# M36B register map
File version: 0.1
TOSHIBA Cortex-M3 MCU
Registers are 32-bit, read-write, reset 0x0 unless marked. A register's access mark holds for its fields unless they carry their own. Offsets are from the block's base; lines under a group give offsets from that group; [hi:lo] are bit positions; {n}, {i} and the like mark numbered series; 'fields as' and 'values as' point back to an identical list; <NAME> marks a mode.

## Memory map
0x40040000 SSP0 size 0x28 — Synchronous Serial Port
0x40041000 SSP1 size 0x28
0x40042000 SSP2 size 0x28
0x40048000 UART0 blocks up to offset 0x4C — ARM Prime Cell PL011
0x40049000 UART1 blocks up to offset 0x4C
0x4004C000 DMAA blocks up to offset 0x50 — DMA Controller
0x4004D000 DMAB blocks up to offset 0x50
0x40050000 AD blocks up to offset 0x78 — Analog-to-Digital Converter (AD)
0x4005C000 EXB blocks up to offset 0x50 — External Bus Interface(EXB)
0x40066000 ADILV blocks up to offset 0x14 — ADC
0x400C0000 PA blocks up to offset 0x3C — General Purpose Input_Output Port (PA)
0x400C0100 PB blocks up to offset 0x3C — General Purpose Input_Output Port (PB)
0x400C0200 PC blocks up to offset 0x3C — General Purpose Input_Output Port (PC)
0x400C0400 PE blocks up to offset 0x3C — General Purpose Input_Output Port (PE)
0x400C0500 PF blocks up to offset 0x3C — General Purpose Input_Output Port (PF)
0x400C0600 PG blocks up to offset 0x3C — General Purpose Input_Output Port (PG)
0x400C0700 PH blocks up to offset 0x3C — General Purpose Input_Output Port (PH)
0x400C0800 PI blocks up to offset 0x3C — General Purpose Input_Output Port (PI)
0x400C0900 PJ blocks up to offset 0x3C — General Purpose Input_Output Port (PJ)
0x400C0A00 PK blocks up to offset 0x3C — General Purpose Input_Output Port (PK)
0x400C0B00 PL blocks up to offset 0x3C — General Purpose Input_Output Port (PL)
0x400C4000 TB0 size 0x30 — 16-bit Timer_Event Counter (TB)
0x400C4100 TB1 size 0x30
0x400C4200 TB2 size 0x30
0x400C4300 TB3 size 0x30
0x400C4400 TB4 size 0x30
0x400C4500 TB5 size 0x30
0x400C4600 TB6 size 0x30
0x400C4700 TB7 size 0x30
0x400C7000 MT0 size 0x5C — 16-bit Multi-Purpose Timer (MPT-TMR_IGBT)
0x400C7100 MT1 size 0x5C
0x400C7200 MT2 size 0x5C
0x400C7300 MT3 size 0x5C
0x400CC000 RTC blocks up to offset 0x12 — Real Time Clock (RTC)
0x400E0000 SBI0 size 0x18 — Serial Bus Interface (SBI)
0x400E0100 SBI1 size 0x18
0x400E0200 SBI2 size 0x18
0x400E1000 SC0 size 0x34 — Serial Channel (SC)
0x400E1100 SC1 size 0x34
0x400E1200 SC2 size 0x34
0x400E1300 SC3 size 0x34
0x400E7000 RMC size 0x38 — Remote Control Signal Preprocessor (RMC)
0x400F1000 OFD size 0x24 — Oscillation Frequency Detector (OFD)
0x400F2000 WD size 0x8 — Watchdog Timer (WD)
0x400F3000 CG blocks up to offset 0x6C — Clock Generator (CG)
0x400F3200 TRMOSC size 0x10 — Internal High-speed Oscillation Adjustment
0x400F4000 LVD size 0xC — Low Voltage detector control register
0x400F6000 MTPD blocks up to offset 0x60 — 16-bit Multi-Purpose Timer (MPT-PMD)
0x400F7000 EN size 0x10 — Encoder Input (ENC)
0x41FFF000 FC blocks up to offset 0x24 — Flash Control (FC)

## SSP0 — Synchronous Serial Port
Base 0x40040000
Same registers: SSP1 0x40041000, SSP2 0x40042000
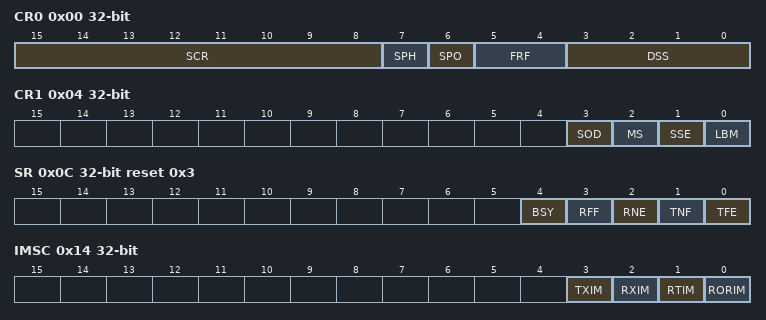
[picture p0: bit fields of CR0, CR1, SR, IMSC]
0x00 CR0 — SSP Control Register 0
  [15:8] SCR, [7] SPH, [6] SPO, [5:4] FRF, [3:0] DSS
0x04 CR1 — SSP Control Register 1
  [3] SOD, [2] MS, [1] SSE, [0] LBM
0x08 DR — SSP Data Register
  [15:0] DATA
0x0C SR ro reset 0x3 — SSP Status Register
  [4] BSY, [3] RFF, [2] RNE, [1] TNF, [0] TFE
0x10 CPSR — SSP Clock Prescaler Register
  [7:0] CPSDVSR
0x14 IMSC — SSP Interrupt Mask Set and Clear Register
  [3] TXIM, [2] RXIM, [1] RTIM, [0] RORIM
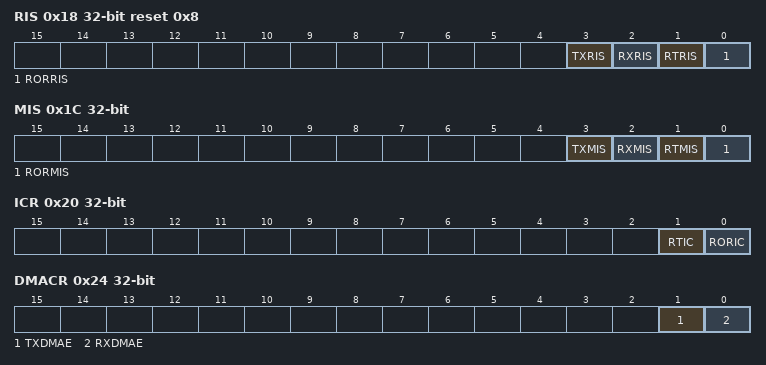
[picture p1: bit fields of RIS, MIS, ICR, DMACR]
0x18 RIS ro reset 0x8 — SSP Raw Interrupt Status Register
  [3] TXRIS, [2] RXRIS, [1] RTRIS, [0] RORRIS
0x1C MIS ro — SSP Masked Interrupt Status Register
  [3] TXMIS, [2] RXMIS, [1] RTMIS, [0] RORMIS
0x20 ICR wo reset not defined — SSP Interrupt Clear Register
  [1] RTIC, [0] RORIC
0x24 DMACR — SSP DMA Control Register
  [1] TXDMAE, [0] RXDMAE

## UART0 — ARM Prime Cell PL011
Base 0x40048000
Same registers: UART1 0x40049000
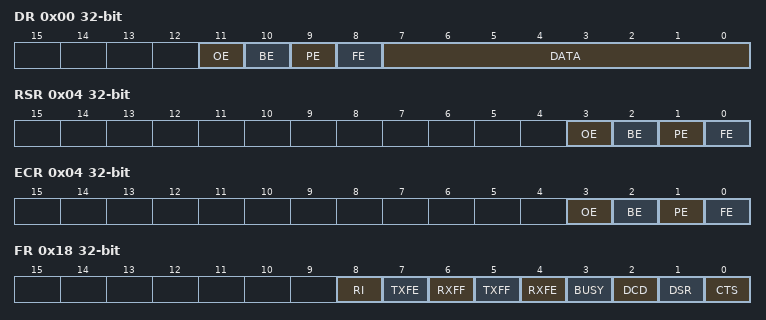
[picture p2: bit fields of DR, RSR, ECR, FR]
0x00 DR — Data Register
  [11] OE ro, [10] BE ro, [9] PE ro, [8] FE ro, [7:0] DATA
0x04 RSR ro — Receive Status Register
  [3] OE, [2] BE, [1] PE, [0] FE
0x04 ECR wo — Error Clear Register
  [3] OE, [2] BE, [1] PE, [0] FE
0x18 FR ro — Flag Register
  [8] RI, [7] TXFE, [6] RXFF, [5] TXFF, [4] RXFE, [3] BUSY, [2] DCD, [1] DSR, [0] CTS
0x20 ILPR — IrDA Low-power Counter register
  [7:0] ILPDVSR
0x24 IBDR — Integer Baud Rate Register
  [15:0] BAUDDIVINT
0x28 FBDR — Fractional Baud Rate Register
  [5:0] BAUDDIVFRAC
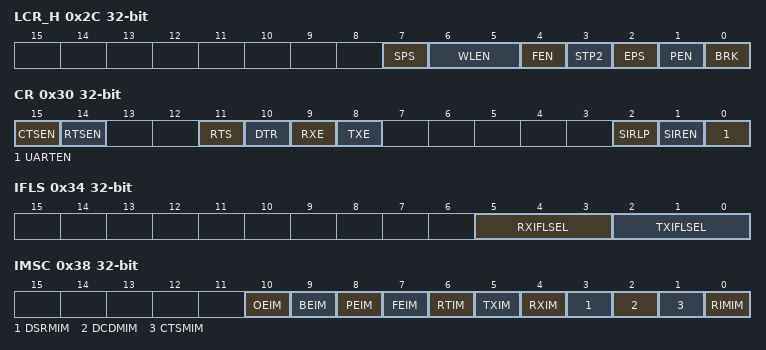
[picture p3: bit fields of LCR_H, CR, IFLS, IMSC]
0x2C LCR_H — Line Control Register
  [7] SPS, [6:5] WLEN, [4] FEN, [3] STP2, [2] EPS, [1] PEN, [0] BRK
0x30 CR — Cntrol Register
  [15] CTSEN, [14] RTSEN, [11] RTS, [10] DTR, [9] RXE, [8] TXE, [2] SIRLP, [1] SIREN, [0] UARTEN
0x34 IFLS — Interrupt FIFO Level Select Register
  [5:3] RXIFLSEL, [2:0] TXIFLSEL
0x38 IMSC — Interrupt Mask set_Clear Register
  [10] OEIM, [9] BEIM, [8] PEIM, [7] FEIM, [6] RTIM, [5] TXIM, [4] RXIM, [3] DSRMIM, [2] DCDMIM, [1] CTSMIM, [0] RIMIM
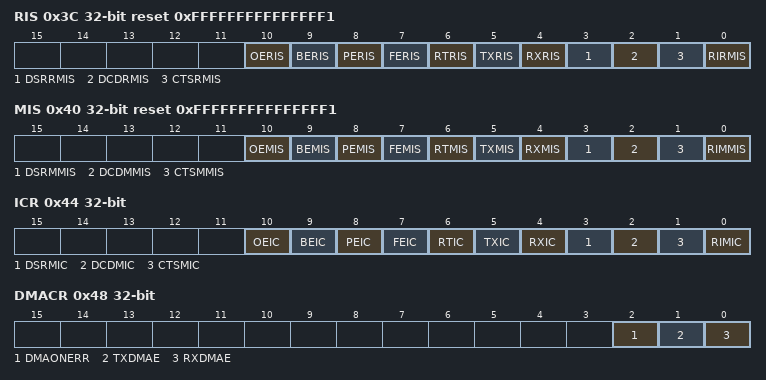
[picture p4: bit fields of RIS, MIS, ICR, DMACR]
0x3C RIS ro reset 0xFFFFFFFFFFFFFFF1 — Raw Interrupt Status Register
  [10] OERIS, [9] BERIS, [8] PERIS, [7] FERIS, [6] RTRIS, [5] TXRIS, [4] RXRIS, [3] DSRRMIS, [2] DCDRMIS, [1] CTSRMIS, [0] RIRMIS
0x40 MIS ro reset 0xFFFFFFFFFFFFFFF1 — Masked Interrupt Status Register
  [10] OEMIS, [9] BEMIS, [8] PEMIS, [7] FEMIS, [6] RTMIS, [5] TXMIS, [4] RXMIS, [3] DSRMMIS, [2] DCDMMIS, [1] CTSMMIS, [0] RIMMIS
0x44 ICR wo — Interrupt Clear Register
  [10] OEIC, [9] BEIC, [8] PEIC, [7] FEIC, [6] RTIC, [5] TXIC, [4] RXIC, [3] DSRMIC, [2] DCDMIC, [1] CTSMIC, [0] RIMIC
0x48 DMACR — DMA Control Register
  [2] DMAONERR, [1] TXDMAE, [0] RXDMAE
